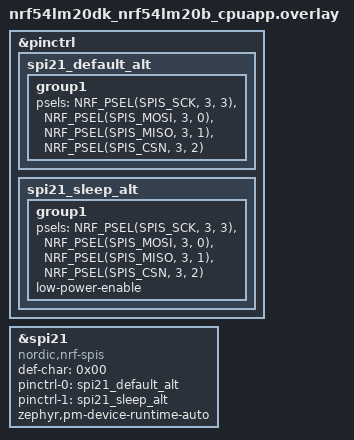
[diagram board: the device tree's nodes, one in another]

&pinctrl {
	spi21_default_alt: spi21_default_alt {
		group1 {
			psels = <NRF_PSEL(SPIS_SCK, 3, 3)>,
				<NRF_PSEL(SPIS_MOSI, 3, 0)>,
				<NRF_PSEL(SPIS_MISO, 3, 1)>,
				<NRF_PSEL(SPIS_CSN, 3, 2)>;
		};
	};

	spi21_sleep_alt: spi21_sleep_alt {
		group1 {
			psels = <NRF_PSEL(SPIS_SCK, 3, 3)>,
				<NRF_PSEL(SPIS_MOSI, 3, 0)>,
				<NRF_PSEL(SPIS_MISO, 3, 1)>,
				<NRF_PSEL(SPIS_CSN, 3, 2)>;
			low-power-enable;
		};
	};
};

dut_spis: &spi21 {
	compatible = "nordic,nrf-spis";
	status = "okay";
	def-char = <0x00>;
	pinctrl-0 = <&spi21_default_alt>;
	pinctrl-1 = <&spi21_sleep_alt>;
	pinctrl-names = "default", "sleep";
	/delete-property/ rx-delay-supported;
	/delete-property/ rx-delay;
	zephyr,pm-device-runtime-auto;
};
